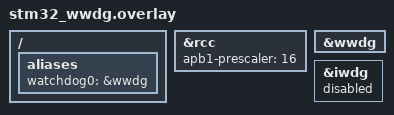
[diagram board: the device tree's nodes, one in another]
/*
 * Copyright (c) 2022 STMicroelectronics
 *
 * SPDX-License-Identifier: Apache-2.0
 */

/ {
	aliases {
		watchdog0 = &wwdg;
	};
};

&rcc {
	/* Reduce APB1 speed to achieve test window timings */
	apb1-prescaler = <16>;
};

&wwdg {
	status = "okay";
};

&iwdg {
	status = "disabled";
};
